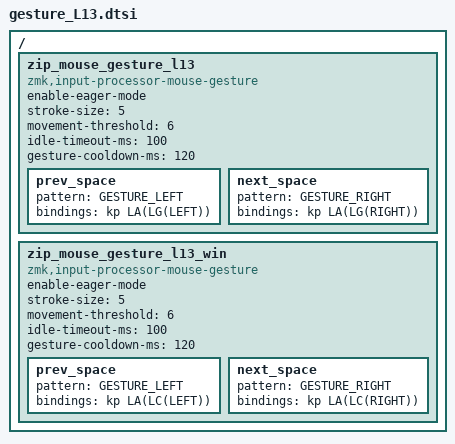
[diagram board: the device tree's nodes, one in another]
/ {
    zip_mouse_gesture_l13: zip_mouse_gesture_l13 {
        compatible = "zmk,input-processor-mouse-gesture";
        #input-processor-cells = <0>;
        enable-eager-mode;
        stroke-size = <5>;
        movement-threshold = <6>;
        idle-timeout-ms = <100>;
        gesture-cooldown-ms = <120>;

        prev_space { pattern = <GESTURE_LEFT>; bindings = <&kp LA(LG(LEFT))>; };
        next_space { pattern = <GESTURE_RIGHT>; bindings = <&kp LA(LG(RIGHT))>; };
    };

    zip_mouse_gesture_l13_win: zip_mouse_gesture_l13_win {
        compatible = "zmk,input-processor-mouse-gesture";
        #input-processor-cells = <0>;
        enable-eager-mode;
        stroke-size = <5>;
        movement-threshold = <6>;
        idle-timeout-ms = <100>;
        gesture-cooldown-ms = <120>;

        prev_space { pattern = <GESTURE_LEFT>; bindings = <&kp LA(LC(LEFT))>; };
        next_space { pattern = <GESTURE_RIGHT>; bindings = <&kp LA(LC(RIGHT))>; };
    };
};
